# DDRSS0_CTL_CFG register map
Vendor: Texas Instruments
Peripheral module from a debugger description file (folder am65x).
Registers are 32-bit, read-write, reset 0x0 unless marked. A register's access mark holds for its fields unless they carry their own. Offsets are as the file gives them; lines under a group give offsets from that group; [hi:lo] are bit positions; {n}, {i} and the like mark numbered series; 'fields as' and 'values as' point back to an identical list; <NAME> marks a mode.

## DDRSS0_CTL_CFG (part 1 of 5)
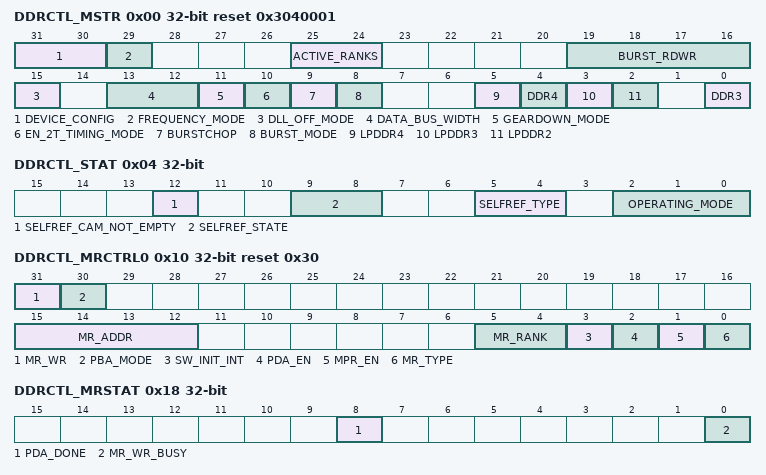
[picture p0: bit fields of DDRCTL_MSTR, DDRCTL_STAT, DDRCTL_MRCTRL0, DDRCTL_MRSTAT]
0x00 DDRCTL_MSTR reset 0x3040001 — Master Register0
  [31:30] DEVICE_CONFIG — Indicates the configuration of the device used in the system.- 00 - x4 device - 01 - x8 device - 10 - x16 device - 11 - x32 device Programming Mode: Static
  [29] FREQUENCY_MODE — Choose which registers are used.- 0 - Original registers - 1 - When UMCTL2_FREQUENCY_NUM=2: FREQ1 registers When UMCTL2_FREQUENCY_NUM&gt;2: Choosen by MSTR2.target_frequency register Programming Mode: Quasi-dynamic Group 2
  [25:24] ACTIVE_RANKS — Only present for multi-rank configurations.Each bit represents one rank. For two-rank configurations, only bits[25:24] are present. - 1 - populated - 0 - unpopulated LSB is the lowest rank number. For 2 ranks following combinations are legal: - 01 - One rank - 11 - Two ranks - Others - Reserved. For 4 ranks following combinations are legal: - 0001 - One rank - 0011 - Two ranks - 0111 - Three ranks - 1111 - Four ranks Programming Mode: Static
  [19:16] BURST_RDWR — SDRAM burst length used: -0001 - Burst length of 2 (only supported for mDDR) - 0010 - Burst length of 4 - 0100 - Burst length of 8 - 1000 - Burst length of 16 (only supported for mDDR, LPDDR2, and LPDDR4) All other values are reserved. This controls the burst size used to access the SDRAM. This must match the burst length mode register setting in the SDRAM. (For BC4/8 on-the-fly mode of DDR3 and DDR4, set this field to 0x0100) Burst length of 2 is not supported with AXI ports when MEMC_BURST_LENGTH is 8. Burst length of 2 is only supported when the controller is operating in 1:1 frequency mode. For DDR3, DDR4 and LPDDR3, this must be set to 0x0100 (BL8). For LPDDR4, this must be set to 0x1000 (BL16). Programming Mode: Static
  [15] DLL_OFF_MODE — Set to 1 when the uMCTL2 and DRAM has to be put in DLL-off mode for low frequency operation.Set to 0 to put uMCTL2 and DRAM in DLL-on mode for normal frequency operation. If DDR4 CRC/parity retry is enabled (DDRCTL_CRCPARCTL1.crc_parity_retry_enable = 1), dll_off_mode is not supported, and this bit must be set to '0'. Programming Mode: Quasi-dynamic Group 2
  [13:12] DATA_BUS_WIDTH — Selects proportion of DQ bus width that is used by the SDRAM -00 - Full DQ bus width to SDRAM - 01 - Half DQ bus width to SDRAM - 10 - Quarter DQ bus width to SDRAM - 11 - Reserved. Note that half bus width mode is only supported when the SDRAM bus width is a multiple of 16, and quarter bus width mode is only supported when the SDRAM bus width is a multiple of 32 and the configuration parameter MEMC_QBUS_SUPPORT is set. Bus width refers to DQ bus width (excluding any ECC width). Programming Mode: Static
  [11] GEARDOWN_MODE — 1 indicates put the DRAM in geardown mode (2N) and 0 indicates put the DRAM in normal mode (1N).This register can be changed, only when the Controller is in self-refresh mode. This signal must be set the same value as MR3 bit A3. Note: Geardown mode is not supported if the configuration parameter MEMC_CMD_RTN2IDLE is set Note: Geardown mode is not supported if the configuration parameter UMCTL2_SHARED_AC is set (in Shared-AC mode) and the register value is don't care Programming Mode: Quasi-dynamic Group 2
  [10] EN_2T_TIMING_MODE — If 1, then uMCTL2 uses 2T timing.Otherwise, uses 1T timing. In 2T timing, all command signals (except chip select) are held for 2 clocks on the SDRAM bus. Chip select is asserted on the second cycle of the command Note: 2T timing is not supported in LPDDR2/LPDDR3/LPDDR4 mode Note: 2T timing is not supported if the configuration parameter MEMC_CMD_RTN2IDLE is set Note: 2T timing is not supported in DDR4 geardown mode. Note: 2T timing is not supported in Shared-AC dual channel mode and the register value is don't care. Programming Mode: Static
  [9] BURSTCHOP — When set, enable burst-chop (BC4 or 8 on-the-fly) in DDR3/DDR4.Burst Chop for Reads is exercised only in HIF configurations (UMCTL2_INCL_ARB not set) and if in full bus width mode (DDRCTL_MSTR.data_bus_width = 00) and if MEMC_BURST_LENGTH=8 or 16. Burst Chop for Writes is exercised only if Partial Writes enabled (UMCTL2_PARTIAL_WR=1) and if CRC is disabled (DDRCTL_CRCPARCTL1.crc_enable = 0). If DDR4 CRC/parity retry is enabled (DDRCTL_CRCPARCTL1.crc_parity_retry_enable = 1), burst chop is not supported, and this bit must be set to '0'. BC4 (fixed) mode is not supported. Programming Mode: Static
  [8] BURST_MODE — Indicates burst mode.0 - Sequential burst mode 1 - Interleaved burst mode For LPDDR3 and LPDDR4, this must be set to 0 (sequential mode). Programming Mode: Static
  [5] LPDDR4 — Select LPDDR4 SDRAM -1 - LPDDR4 SDRAM device in use. - 0 - non-LPDDR4 device in use Present only in designs configured to support LPDDR4. Programming Mode: Static
  [4] DDR4 — Select DDR4 SDRAM -1 - DDR4 SDRAM device in use. - 0 - non-DDR4 device in use Present only in designs configured to support DDR4. Programming Mode: Static
  [3] LPDDR3 — Select LPDDR3 SDRAM -1 - LPDDR3 SDRAM device in use. - 0 - non-LPDDR3 device in use Present only in designs configured to support LPDDR3. Programming Mode: Static
  [2] LPDDR2 — Select LPDDR2 SDRAM -1 - LPDDR2 SDRAM device in use. - 0 - non-LPDDR2 device in use Present only in designs configured to support LPDDR2. Programming Mode: Static
  [0] DDR3 — Select DDR3 SDRAM -1 - DDR3 SDRAM device in use - 0 - non-DDR3 SDRAM device in use Only present in designs that support DDR3. Programming Mode: Static
0x04 DDRCTL_STAT ro — Operating Mode Status Register
  [12] SELFREF_CAM_NOT_EMPTY — Self refresh with CAMs not empty.Set to 1 when Self Refresh is entered but CAMs are not drained. Cleared after exiting Self Refresh. Programming Mode: Dynamic
  [9:8] SELFREF_STATE — Self refresh state.This indicates self refresh or self refresh power down state for LPDDR4. This register is used for frequency change and MRR/MRW access during self refresh. - 00 - SDRAM is not in Self Refresh. - 01 - Self refresh 1 - 10 - Self refresh power down - 11 - Self refresh 2 Programming Mode: Dynamic
  [5:4] SELFREF_TYPE — Flags if Self Refresh (except LPDDR4) or SR-Powerdown (LPDDR4) is entered and if it was under Automatic Self Refresh control only or not.- 00 - SDRAM is not in Self Refresh (except LPDDR4) or SR-Powerdown (LPDDR4). If retry is enabled by CRCPARCTRL1.crc_parity_retry_enable, this also indicates SRE command is still in parity error window or retry is in-progress. - 11 - SDRAM is in Self Refresh (except LPDDR4) or SR-Powerdown (LPDDR4), which was caused by Automatic Self Refresh only. If retry is enabled, this guarantees SRE command is executed correctly without parity error. - 10 - SDRAM is in Self Refresh (except LPDDR4) or SR-Powerdown (LPDDR4), which was not caused solely under Automatic Self Refresh control. It could have been caused by Hardware Low Power Interface and/or Software (DDRCTL_PWRCTL.selfref_sw). If retry is enabled, this guarantees SRE command is executed correctly without parity error. - 01 - SDRAM is in Self Refresh, which was caused by PHY Master Request. Programming Mode: Dynamic
  [2:0] OPERATING_MODE — Operating mode.This is 3-bits wide in configurations with mDDR/LPDDR2/LPDDR3/LPDDR4/DDR4 support and 2-bits in all other configurations. non-mDDR/LPDDR2/LPDDR3/LPDDR4 and non-DDR4 designs: - 00 - Init - 01 - Normal - 10 - Power-down - 11 - Self refresh mDDR/LPDDR2/LPDDR3 or DDR4 designs: - 000 - Init - 001 - Normal - 010 - Power-down - 011 - Self refresh - 1XX - Deep power-down / Maximum Power Saving Mode LPDDR4 designs: - 000 - Init - 001 - Normal - 010 - Power-down - 011 - Self refresh / Self refresh power-down Programming Mode: Dynamic
0x10 DDRCTL_MRCTRL0 access not given reset 0x30 — Mode Register Read/Write Control Register 0. Note: Do not enable more than one of the following fields simultaneously: - sw_init_int - pda_en - mpr_en
  [31] MR_WR — Setting this register bit to 1 triggers a mode register read or write operation.When the MR operation is complete, the uMCTL2 automatically clears this bit. The other register fields of this register must be written in a separate APB transaction, before setting this mr_wr bit. It is recommended NOT to set this signal if in Init, Deep power-down or MPSM operating modes. Programming Mode: Dynamic (access W1S)
  [30] PBA_MODE rw — Indicates whether PBA access is executed.When setting this bit to 1 along with setting pda_en to 1, uMCTL2 initiates PBA access instead of PDA access. - 0 - Per DRAM Addressability mode - 1 - Per Buffer Addressability mode The completion of PBA access is confirmed by DDRCTL_MRSTAT.pda_done in the same way as PDA. Programming Mode: Dynamic
  [15:12] MR_ADDR rw — Address of the mode register that is to be written to.- 0000 - MR0 - 0001 - MR1 - 0010 - MR2 - 0011 - MR3 - 0100 - MR4 - 0101 - MR5 - 0110 - MR6 - 0111 - MR7 Don't Care for LPDDR2/LPDDR3/LPDDR4 (see DDRCTL_MRCTRL1.mr_data for mode register addressing in LPDDR2/LPDDR3/LPDDR4) This signal is also used for writing to control words of the register chip on RDIMMs/LRDIMMs. In that case, it corresponds to the bank address bits sent to the RDIMM/LRDIMM In case of DDR4, the bit[3:2] corresponds to the bank group bits. Therefore, the bit[3] as well as the bit[2:0] must be set to an appropriate value which is considered both the Address Mirroring of UDIMMs/RDIMMs/LRDIMMs and the Output Inversion of RDIMMs/LRDIMMs. Programming Mode: Dynamic
  [5:4] MR_RANK rw — Controls which rank is accessed byDDRCTL_MRCTRL0.mr_wr. Normally, it is desired to access all ranks, so all bits should be set to 1. However, for multi-rank UDIMMs/RDIMMs/LRDIMMs which implement address mirroring, it may be necessary to access ranks individually. Examples (assume uMCTL2 is configured for 4 ranks): - 0x1 - select rank 0 only - 0x2 - select rank 1 only - 0x5 - select ranks 0 and 2 - 0xA - select ranks 1 and 3 - 0xF - select ranks 0, 1, 2 and 3 Programming Mode: Dynamic
  [3] SW_INIT_INT rw — Indicates whether Software intervention is allowed viaDDRCTL_MRCTRL0/DDRCTL_MRCTRL1 before automatic SDRAM initialization routine or not. For DDR4, this bit can be used to initialize the DDR4 RCD (MR7) before automatic SDRAM initialization. For LPDDR4, this bit can be used to program additional mode registers before automatic SDRAM initialization if necessary. In LPDDR4 dual channel mode, note that this must be programmed to both channels beforehand. Note that this must be cleared to 0 after completing Software operation. Otherwise, SDRAM initialization routine will not re-start. - 0 - Software intervention is not allowed - 1 - Software intervention is allowed Programming Mode: Dynamic
  [2] PDA_EN rw — Indicates whether the mode register operation is MRS in PDA mode or not -0 - MRS - 1 - MRS in Per DRAM Addressability mode Note that when pba_mode=1, PBA access is initiated instead of PDA access. Programming Mode: Dynamic
  [1] MPR_EN rw — Indicates whether the mode register operation is MRS or WR/RD for MPR (only supported for DDR4) -0 - MRS - 1 - WR/RD for MPR Programming Mode: Dynamic
  [0] MR_TYPE rw — Indicates whether the mode register operation is read or write.Only used for LPDDR2/LPDDR3/LPDDR4/DDR4. - 0 - Write - 1 - Read Programming Mode: Dynamic
0x14 DDRCTL_MRCTRL1 — Mode Register Read/Write Control Register 1
  [17:0] MR_DATA — Mode register write data for all non-LPDDR2/non-LPDDR3/non-LPDDR4 modes.For LPDDR2/LPDDR3/LPDDR4, DDRCTL_MRCTRL1[15:0] are interpreted as [15:8] MR Address [7:0] MR data for writes, don't care for reads. This is 18-bits wide in configurations with DDR4 support and 16-bits in all other configurations. Programming Mode: Dynamic
0x18 DDRCTL_MRSTAT ro — Mode Register Read/Write Status Register
  [8] PDA_DONE — The SoC core may initiate a MR write operation in PDA/PBA mode only if this signal is low.This signal goes high when three consecutive MRS commands related to the PDA/PBA mode are issued to the SDRAM. This signal goes low when DDRCTL_MRCTRL0.pda_en becomes 0. Therefore, it is recommended to write DDRCTL_MRCTRL0.pda_en to 0 after this signal goes high in order to prepare to perform PDA operation next time. - 0 - Indicates that mode register write operation related to PDA/PBA is in progress or has not started yet. - 1 - Indicates that mode register write operation related to PDA/PBA has competed. Programming Mode: Dynamic
  [0] MR_WR_BUSY — The SoC core may initiate a MR write operation only if this signal is low.This signal goes high in the clock after the uMCTL2 accepts the MRW/MRR request. It goes low when the MRW/MRR command is issued to the SDRAM. It is recommended not to perform MRW/MRR commands when 'DDRCTL_MRSTAT.mr_wr_busy' is high. - 0 - Indicates that the SoC core can initiate a mode register write operation - 1 - Indicates that mode register write operation is in progress Programming Mode: Dynamic
0x1C DDRCTL_MRCTRL2 — Mode Register Read/Write Control Register 2
  [31:0] MR_DEVICE_SEL — Indicates the device(s) to be selected during the MRS that happens in PDA mode.Each bit is associated with one device. For example, bit[0] corresponds to Device 0, bit[1] to Device 1 etc. A '1' should be programmed to indicate that the MRS command should be applied to that device. A '0' indicates that the MRS commands should be skipped for that device. Programming Mode: Dynamic
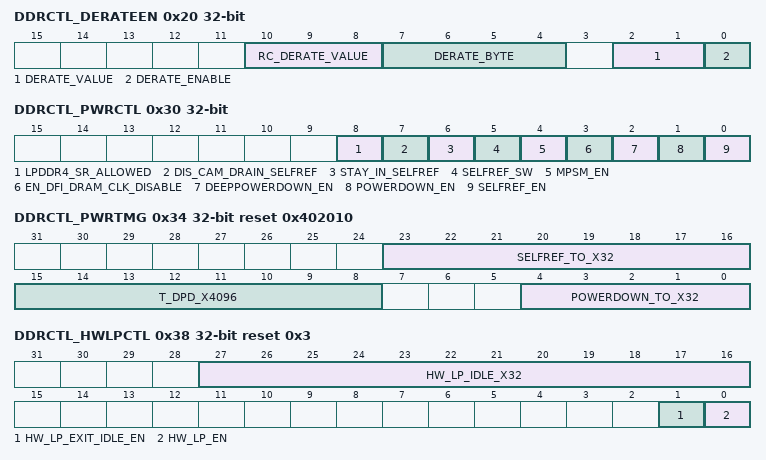
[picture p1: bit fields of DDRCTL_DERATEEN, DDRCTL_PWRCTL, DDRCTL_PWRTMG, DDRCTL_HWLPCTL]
0x20 DDRCTL_DERATEEN — Temperature Derate Enable Register
  [10:8] RC_DERATE_VALUE — Derate value of tRC for LPDDR4 - 0 - Derating uses +1. - 1 - Derating uses +2. - 2 - Derating uses +3. - 3 - Derating uses +4. Present only in designs configured to support LPDDR4. The required number of cycles for derating can be determined by dividing 3.75ns by the core_ddrc_core_clk period, and rounding up the next integer. Programming Mode: Quasi-dynamic Group 2 and Group 4
  [7:4] DERATE_BYTE — Derate byte Present only in designs configured to support LPDDR2/LPDDR3/LPDDR4 Indicates which byte of the MRR data is used for derating.The maximum valid value depends on MEMC_DRAM_TOTAL_DATA_WIDTH. Programming Mode: Static
  [2:1] DERATE_VALUE — Derate value -0 - Derating uses +1. - 1 - Derating uses +2. Present only in designs configured to support LPDDR2/LPDDR3/LPDDR4 Set to 0 for all LPDDR2 speed grades as derating value of +1.875 ns is less than a core_ddrc_core_clk period. For LPDDR3/4, if the period of core_ddrc_core_clk is less than 1.875ns, this register field should be set to 1 otherwise it should be set to 0. Programming Mode: Quasi-dynamic Group 2 and Group 4
  [0] DERATE_ENABLE — Enables derating -0 - Timing parameter derating is disabled - 1 - Timing parameter derating is enabled using MR4 read value. Present only in designs configured to support LPDDR2/LPDDR3/LPDDR4 This field must be set to '0' for non-LPDDR2/LPDDR3/LPDDR4 mode. Programming Mode: Dynamic
0x24 DDRCTL_DERATEINT reset 0x800000 — Temperature Derate Interval Register
  [31:0] MR4_READ_INTERVAL — Interval between two MR4 reads, used to derate the timing parameters.Present only in designs configured to support LPDDR2/LPDDR3/LPDDR4. This register must not be set to zero. Unit: DFI clock cycle. Programming Mode: Static
0x30 DDRCTL_PWRCTL — Low Power Control Register
  [8] LPDDR4_SR_ALLOWED — Indicates whether transition from SR-PD to SR and back to SR-PD is allowed.This register field cannot be modified while DDRCTL_PWRCTL.selfref_sw==1. - 0 - SR-PD -&gt; SR -&gt; SR-PD not allowed - 1 - SR-PD -&gt; SR -&gt; SR-PD allowed Programming Mode: Dynamic
  [7] DIS_CAM_DRAIN_SELFREF — Indicates whether skipping CAM draining is allowed when entering Self-Refresh.This register field cannot be modified while DDRCTL_PWRCTL.selfref_sw==1. - 0 - CAMs must be empty before entering SR - 1 - CAMs are not emptied before entering SR Programming Mode: Dynamic
  [6] STAY_IN_SELFREF — Self refresh state is an intermediate state to enter to Self refresh power down state or exit Self refresh power down state for LPDDR4.This register controls transition from the Self refresh state. - 1 - Prohibit transition from Self refresh state - 0 - Allow transition from Self refresh state Programming Mode: Dynamic
  [5] SELFREF_SW — A value of 1 to this register causes system to move to Self Refresh state immediately, as long as it is not in INIT or DPD/MPSM operating_mode.This is referred to as Software Entry/Exit to Self Refresh. - 1 - Software Entry to Self Refresh - 0 - Software Exit from Self Refresh Programming Mode: Dynamic
  [4] MPSM_EN — When this is 1, the uMCTL2 puts the SDRAM into maximum power saving mode when the transaction store is empty.This register must be reset to '0' to bring uMCTL2 out of maximum power saving mode. Present only in designs configured to support DDR4. For non-DDR4, this register should not be set to 1. Note that MPSM is not supported when using a DWC DDR PHY, if the PHY parameter DWC_AC_CS_USE is disabled, as the MPSM exit sequence requires the chip-select signal to toggle. FOR PERFORMANCE ONLY. Programming Mode: Dynamic
  [3] EN_DFI_DRAM_CLK_DISABLE — Enable the assertion of dfi_dram_clk_disable whenever a clock is not required by the SDRAM.If set to 0, dfi_dram_clk_disable is never asserted. Assertion of dfi_dram_clk_disable is as follows: In DDR2/DDR3, can only be asserted in Self Refresh. In DDR4, can be asserted in following: - in Self Refresh. - in Maximum Power Saving Mode In mDDR/LPDDR2/LPDDR3, can be asserted in following: - in Self Refresh - in Power Down - in Deep Power Down - during Normal operation (Clock Stop) In LPDDR4, can be asserted in following: - in Self Refresh Power Down - in Power Down - during Normal operation (Clock Stop) Programming Mode: Dynamic
  [2] DEEPPOWERDOWN_EN — When this is 1, uMCTL2 puts the SDRAM into deep power-down mode when the transaction store is empty.This register must be reset to '0' to bring uMCTL2 out of deep power-down mode. Controller performs automatic SDRAM initialization on deep power-down exit. Present only in designs configured to support mDDR or LPDDR2 or LPDDR3. For non-mDDR/non-LPDDR2/non-LPDDR3, this register should not be set to 1. FOR PERFORMANCE ONLY. Programming Mode: Dynamic
  [1] POWERDOWN_EN — If true then the uMCTL2 goes into power-down after a programmable number of cycles 'maximum idle clocks before power down' (DDRCTL_PWRTMG.powerdown_to_x32). This register bit may be re-programmed during the course of normal operation. Programming Mode: Dynamic
  [0] SELFREF_EN — If true then the uMCTL2 puts the SDRAM into Self Refresh after a programmable number of cycles 'maximum idle clocks before Self Refresh (DDRCTL_PWRTMG.selfref_to_x32)'. This register bit may be re-programmed during the course of normal operation. Programming Mode: Dynamic
0x34 DDRCTL_PWRTMG reset 0x402010 — Low Power Timing Register
  [23:16] SELFREF_TO_X32 — After this many clocks of the DDRC command channel being idle the uMCTL2 automatically puts the SDRAM into Self Refresh.The DDRC command channel is considered idle when there are no HIF commands outstanding. This must be enabled in the DDRCTL_PWRCTL.selfref_en. Unit: Multiples of 32 DFI clocks. FOR PERFORMANCE ONLY. Programming Mode: Static
  [15:8] T_DPD_X4096 — Minimum deep power-down time.For mDDR, value from the JEDEC specification is 0 as mDDR exits from deep power-down mode immediately after DDRCTL_PWRCTL.deeppowerdown_en is de-asserted. For LPDDR2/LPDDR3, value from the JEDEC specification is 500us. Unit: Multiples of 4096 DFI clocks. Present only in designs configured to support mDDR, LPDDR2 or LPDDR3. FOR PERFORMANCE ONLY. Programming Mode: Static
  [4:0] POWERDOWN_TO_X32 — After this many clocks of the DDRC command channel being idle the uMCTL2 automatically puts the SDRAM into power-down.The DDRC command channel is considered idle when there are no HIF commands outstanding. This must be enabled in the DDRCTL_PWRCTL.powerdown_en. Unit: Multiples of 32 DFI clocks FOR PERFORMANCE ONLY. Programming Mode: Static
0x38 DDRCTL_HWLPCTL reset 0x3 — Hardware Low Power Control Register
  [27:16] HW_LP_IDLE_X32 — Hardware idle period.The cactive_ddrc output is driven low if the DDRC command channel is idle for hw_lp_idle * 32 cycles if not in INIT or DPD/MPSM operating_mode. The DDRC command channel is considered idle when there are no HIF commands outstanding. The hardware idle function is disabled when hw_lp_idle_x32=0. Unit: Multiples of 32 DFI clocks. FOR PERFORMANCE ONLY. Programming Mode: Static
  [1] HW_LP_EXIT_IDLE_EN — When this bit is programmed to 1 the cactive_in_ddrc pin of the DDRC can be used to exit from the automatic clock stop, automatic power down or automatic self-refresh modes.Note, it will not cause exit of Self-Refresh that was caused by Hardware Low Power Interface and/or Software (DDRCTL_PWRCTL.selfref_sw). Programming Mode: Static
  [0] HW_LP_EN — Enable for Hardware Low Power Interface.Programming Mode: Quasi-dynamic Group 3
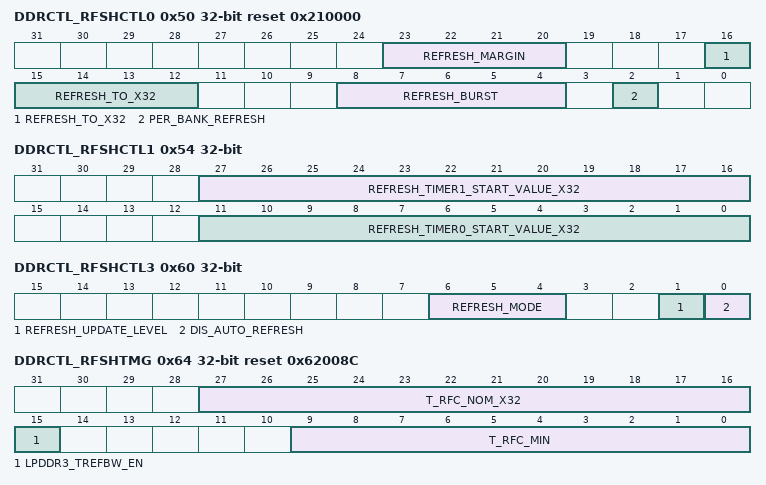
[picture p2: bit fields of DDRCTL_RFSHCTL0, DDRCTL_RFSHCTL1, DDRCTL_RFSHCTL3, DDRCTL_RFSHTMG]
0x50 DDRCTL_RFSHCTL0 reset 0x210000 — Refresh Control Register 0
  [23:20] REFRESH_MARGIN — Threshold value in number of DFI clock cycles before the critical refresh or page timer expires.A critical refresh is to be issued before this threshold is reached. It is recommended that this not be changed from the default value, currently shown as 0x2. It must always be less than internally used t_rfc_nom_x32. Note that, in LPDDR2/LPDDR3/LPDDR4, internally used t_rfc_nom_x32 may be equal to DDRCTL_RFSHTMG.t_rfc_nom_x32&gt;&gt;2 if derating is enabled (DDRCTL_DERATEEN.derate_enable=1). Otherwise, internally used t_rfc_nom_x32 will be equal to DDRCTL_RFSHTMG.t_rfc_nom_x32. Unit: Multiples of 32 DFI clocks. Programming Mode: Dynamic - Refresh Related
  [16:12] REFRESH_TO_X32 — If the refresh timer (tRFCnom, also known as tREFI) has expired at least once, but it has not expired (DDRCTL_RFSHCTL0.refresh_burst+1) times yet, then a speculative refresh may be performed. A speculative refresh is a refresh performed at a time when refresh would be useful, but before it is absolutely required. When the SDRAM bus is idle for a period of time determined by this DDRCTL_RFSHCTL0.refresh_to_x32 and the refresh timer has expired at least once since the last refresh, then a speculative refresh is performed. Speculative refreshes continues successively until there are no refreshes pending or until new reads or writes are issued to the uMCTL2. FOR PERFORMANCE ONLY. Unit: Multiples of 32 DFI clocks. Programming Mode: Dynamic - Refresh Related
  [8:4] REFRESH_BURST — The programmed value + 1 is the number of refresh timeouts that is allowed to accumulate before traffic is blocked and the refreshes are forced to execute.Closing pages to perform a refresh is a one-time penalty that must be paid for each group of refreshes. Therefore, performing refreshes in a burst reduces the per-refresh penalty of these page closings. Higher numbers for RFSHCTL.refresh_burst slightly increases utilization lower numbers decreases the worst-case latency associated with refreshes. - 0 - single refresh - 1 - burst-of-2 refresh - 7 - burst-of-8 refresh For information on burst refresh feature refer to section 3.9 of DDR2 JEDEC specification - JESD79-2F.pdf. For DDR2/3, the refresh is always per-rank and not per-bank. The rank refresh can be accumulated over 8*tREFI cycles using the burst refresh feature. In DDR4 mode, according to Fine Granularity feature, 8 refreshes can be postponed in 1X mode, 16 refreshes in 2X mode and 32 refreshes in 4X mode. If using PHY-initiated updates, care must be taken in the setting of DDRCTL_RFSHCTL0.refresh_burst, to ensure that tRFCmax is not violated due to a PHY-initiated update occurring shortly before a refresh burst was due. In this situation, the refresh burst will be delayed until the PHY-initiated update is complete. Programming Mode: Dynamic - Refresh Related
  [2] PER_BANK_REFRESH — -1 - Per bank refresh - 0 - All bank refresh. Per bank refresh allows traffic to flow to other banks. Per bank refresh is not supported by all LPDDR2 devices but should be supported by all LPDDR3/LPDDR4 devices. Present only in designs configured to support LPDDR2/LPDDR3/LPDDR4 Programming Mode: Static
0x54 DDRCTL_RFSHCTL1 — Refresh Control Register 1
  [27:16] REFRESH_TIMER1_START_VALUE_X32 — Refresh timer start for rank 1 (only present in multi-rank configurations).This is useful in staggering the refreshes to multiple ranks to help traffic to proceed. This is explained in Refresh Controls section of architecture chapter. Unit: Multiples of 32 DFI clock cycles. FOR PERFORMANCE ONLY. Programming Mode: Dynamic - Refresh Related
  [11:0] REFRESH_TIMER0_START_VALUE_X32 — Refresh timer start for rank 0 (only present in multi-rank configurations).This is useful in staggering the refreshes to multiple ranks to help traffic to proceed. This is explained in Refresh Controls section of architecture chapter. Unit: Multiples of 32 DFI clock cycles. FOR PERFORMANCE ONLY. Programming Mode: Dynamic - Refresh Related
0x60 DDRCTL_RFSHCTL3 — Refresh Control Register 3
  [6:4] REFRESH_MODE — Fine Granularity Refresh Mode -000 - Fixed 1x (Normal mode) - 001 - Fixed 2x - 010 - Fixed 4x - 101 - Enable on the fly 2x (not supported) - 110 - Enable on the fly 4x (not supported) - Everything else - reserved Note: Only Fixed 1x mode is supported if DDRCTL_RFSHCTL3.dis_auto_refresh = 1. Note: The on-the-fly modes are not supported in this version of the uMCTL2. Note: This must be set up while the Controller is in reset or while the Controller is in self-refresh mode. Changing this during normal operation is not allowed. Making this a dynamic register will be supported in future version of the uMCTL2. Note: This register field has effect only if a DDR4 SDRAM device is in use (DDRCTL_MSTR.ddr4 = 1). Programming Mode: Quasi-dynamic Group 2
  [1] REFRESH_UPDATE_LEVEL — Toggle this signal (either from 0 to 1 or from 1 to 0) to indicate that the refresh register(s) have been updated.refresh_update_level must not be toggled when the DDRC is in reset (core_ddrc_rstn = 0). The refresh register(s) are automatically updated when exiting reset. Programming Mode: Dynamic
  [0] DIS_AUTO_REFRESH — When '1', disable auto-refresh generated by the uMCTL2.When auto-refresh is disabled, the SoC core must generate refreshes using the registers DDRCTL_DBGCMD.rankn_refresh. When dis_auto_refresh transitions from 0 to 1, any pending refreshes are immediately scheduled by the uMCTL2. If DDR4 CRC/parity retry is enabled (DDRCTL_CRCPARCTL1.crc_parity_retry_enable = 1), disable auto-refresh is not supported, and this bit must be set to '0'. (DDR4 only) If FGR mode is enabled (DDRCTL_RFSHCTL3.refresh_mode &gt; 0), disable auto-refresh is not supported, and this bit must be set to '0'. This register field is changeable on the fly. Programming Mode: Dynamic - Refresh Related
0x64 DDRCTL_RFSHTMG reset 0x62008C — Refresh Timing Register
  [27:16] T_RFC_NOM_X32 — tREFI: Average time interval between refreshes per rank (Specification: 7.8us for DDR2, DDR3 and DDR4.See JEDEC specification for mDDR, LPDDR2, LPDDR3 and LPDDR4). For LPDDR2/LPDDR3/LPDDR4: - if using all-bank refreshes (DDRCTL_RFSHCTL0.per_bank_refresh = 0), this register should be set to tREFIab - if using per-bank refreshes (DDRCTL_RFSHCTL0.per_bank_refresh = 1), this register should be set to tREFIpb When the controller is operating in 1:2 frequency ratio mode, program this to (tREFI/2), no rounding up. In DDR4 mode, tREFI value is different depending on the refresh mode. The user should program the appropriate value from the spec based on the value programmed in the refresh mode register. Note that DDRCTL_RFSHTMG.t_rfc_nom_x32 * 32 must be greater than DDRCTL_RFSHTMG.t_rfc_min, and DDRCTL_RFSHTMG.t_rfc_nom_x32 must be greater than 0x1. - Non-DDR4 or DDR4 Fixed 1x mode: DDRCTL_RFSHTMG.t_rfc_nom_x32 must be less than or equal to 0xFFE. - DDR4 Fixed 2x mode: DDRCTL_RFSHTMG.t_rfc_nom_x32 must be less than or equal to 0x7FF. - DDR4 Fixed 4x mode: DDRCTL_RFSHTMG.t_rfc_nom_x32 must be less than or equal to 0x3FF. Unit: Multiples of 32 clocks. Programming Mode: Dynamic - Refresh Related
  [15] LPDDR3_TREFBW_EN — Used only when LPDDR3 memory type is connected.Should only be changed when uMCTL2 is in reset. Specifies whether to use the tREFBW parameter (required by some LPDDR3 devices which comply with earlier versions of the LPDDR3 JEDEC specification) or not: - 0 - tREFBW parameter not used - 1 - tREFBW parameter used Programming Mode: Static
  [9:0] T_RFC_MIN — tRFC (min): Minimum time from refresh to refresh or activate.When the controller is operating in 1:1 mode, t_rfc_min should be set to RoundUp(tRFCmin/tCK). When the controller is operating in 1:2 mode, t_rfc_min should be set to RoundUp(RoundUp(tRFCmin/tCK)/2). In LPDDR2/LPDDR3/LPDDR4 mode: - if using all-bank refreshes, the tRFCmin value in the above equations is equal to tRFCab - if using per-bank refreshes, the tRFCmin value in the above equations is equal to tRFCpb In DDR4 mode, the tRFCmin value in the above equations is different depending on the refresh mode (fixed 1X,2X,4X) and the device density. The user should program the appropriate value from the spec based on the 'refresh_mode' and the device density that is used. Unit: Clocks. Programming Mode: Dynamic - Refresh Related
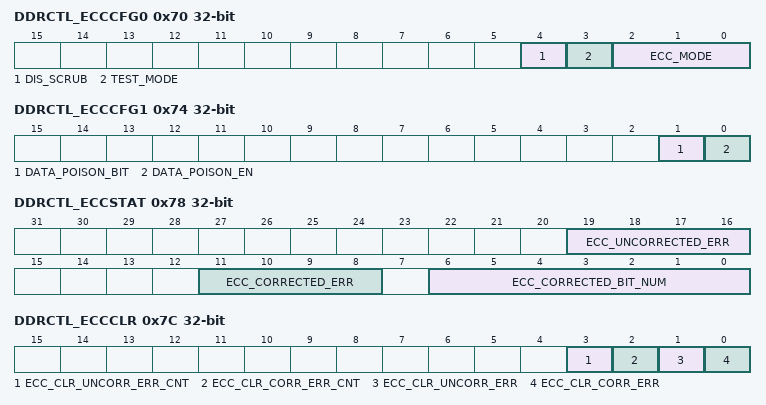
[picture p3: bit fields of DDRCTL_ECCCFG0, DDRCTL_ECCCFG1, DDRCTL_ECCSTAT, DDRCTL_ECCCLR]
0x70 DDRCTL_ECCCFG0 — ECC Configuration Register 0
  [4] DIS_SCRUB — Disable ECC scrubs.Valid only when DDRCTL_ECCCFG0.ecc_mode = 3'b100 or 3'b101 and MEMC_USE_RMW is defined. Note: Scrub is not supported in inline ECC mode and the register value is don't care. Programming Mode: Static
  [3] TEST_MODE — If this bit is set to 1, no ECC is performed, and the ECC byte is accessed directly from co_wu_rxdata_ecc and ra_co_resp_ecc_data.This test mode is only supported with the HIF interface - it is disabled if UMCTL2_INCL_ARB is enabled. This test mode is only supported in full bus width mode. In other words, if DDRCTL_MSTR.data_bus_width is non-zero, this test_mode field must be set to 0. If test_mode is set to 1, the ecc_mode field is ignored. If MEMC_ECC_SUPPORT is 2 (Advanced ECC mode), this test_mode field must be set to 0. Note: test_mode is not supported in inline ECC mode and the register value is don't care. Programming Mode: Static
  [2:0] ECC_MODE — ECC mode indicator -000 - ECC disabled - 100 - ECC enabled - SEC/DED over 1 beat - 101 - ECC enabled - Advanced ECC - all other settings are reserved for future use Programming Mode: Static
0x74 DDRCTL_ECCCFG1 — ECC Configuration Register 1
  [1] DATA_POISON_BIT — Selects whether to poison 1 or 2 bits - if0 -&gt; 2-bit (uncorrectable) data poisoning, if 1 -&gt; 1-bit (correctable) data poisoning, if DDRCTL_ECCCFG1.data_poison_en=1. Valid only when MEMC_ECC_SUPPORT==1 (SECDED ECC mode) Programming Mode: Quasi-dynamic Group 3
  [0] DATA_POISON_EN — Enable ECC data poisoning - introduces ECC errors on writes to address specified by the
0x78 DDRCTL_ECCSTAT ro — SECDED ECC Status Register (Valid only in MEMC_ECC_SUPPORT==1 (SECDED ECC mode))
  [19:16] ECC_UNCORRECTED_ERR — Double-bit error indicators.In sideband ECC mode, 1 bit per ECC lane. When the controller is operating in 1:1 frequency ratio mode, there are only two lanes, so only the lower two bits are used. In inline ECC mode, the register always is 1 bit to indicate uncorrectable error on any lane. Programming Mode: Dynamic
  [11:8] ECC_CORRECTED_ERR — Single-bit error indicators.In sideband ECC mode, 1 bit per ECC lane. When the controller is operating in 1:1 frequency ratio mode, there are only two lanes, so only the lower two bits are used. In inline ECC mode, the register always is 1 bit to indicate correctable error on any lane. Programming Mode: Dynamic
  [6:0] ECC_CORRECTED_BIT_NUM — Bit number corrected by single-bit ECC error.If more than one data lane has an error, the lower data lane is selected. This register is 7 bits wide in order to handle 72 bits of the data present in a single lane. Programming Mode: Static
0x7C DDRCTL_ECCCLR access not given — ECC Clear Register
  [3] ECC_CLR_UNCORR_ERR_CNT — Setting this register bit to 1 clears the currently stored uncorrected ECC error count.The DDRCTL_ECCERRCNT.ecc_uncorr_err_cnt register is cleared by this operation. When the clear operation is complete, the uMCTL2 automatically clears this bit. Programming Mode: Dynamic (access RW1C)
  [2] ECC_CLR_CORR_ERR_CNT — Setting this register bit to 1 clears the currently stored corrected ECC error count.The DDRCTL_ECCERRCNT.ecc_corr_err_cnt register is cleared by this operation. When the clear operation is complete, the uMCTL2 automatically clears this bit. Programming Mode: Dynamic (access RW1C)
  [1] ECC_CLR_UNCORR_ERR — Setting this register bit to 1 clears the currently stored uncorrected ECC error.The DDRCTL_ECCSTAT.ecc_uncorrected_err, ADVECCSTAT.advecc_uncorrected_err, DDRCTL_ECCUADDR0, DDRCTL_ECCUADDR1, DDRCTL_ECCUSYN0, ECCUSYN1 and DDRCTL_ECCUSYN2 registers are cleared by this operation. When the clear operation is complete, the uMCTL2 automatically clears this bit. Programming Mode: Dynamic (access RW1C)
  [0] ECC_CLR_CORR_ERR — Setting this register bit to 1 clears the currently stored corrected ECC error.The DDRCTL_ECCSTAT.ecc_corrected_err, DDRCTL_ECCSTAT.ecc_corrected_bit_num, ADVECCSTAT.advecc_corrected_err, ADVECCSTAT.advecc_num_err_symbol, ADVECCSTAT.advecc_err_symbol_pos, ADVECCSTAT.advecc_err_symbol_bits, DDRCTL_ECCCADDR0, DDRCTL_ECCCADDR1, DDRCTL_ECCCSYN0, ECCCSYN1, DDRCTL_ECCCSYN2, DDRCTL_ECCBITMASK0, ECCBITMASK1 and DDRCTL_ECCBITMASK2 registers are cleared by this operation. When the clear operation is complete, the uMCTL2 automatically clears this bit. Programming Mode: Dynamic (access RW1C)
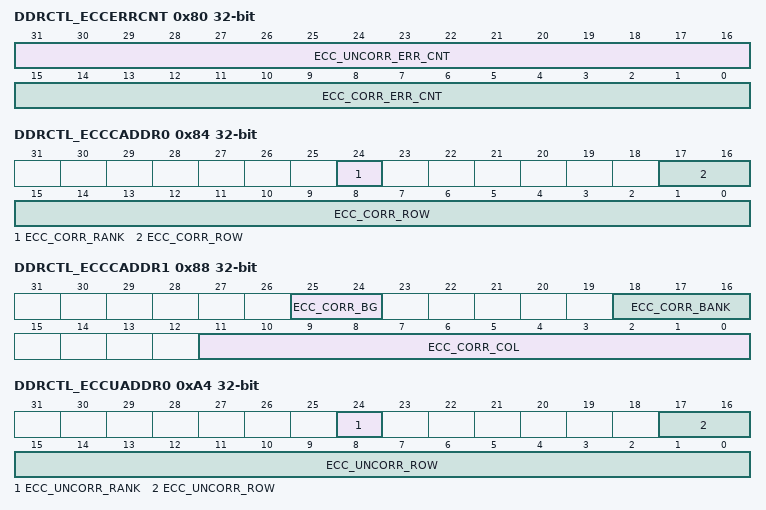
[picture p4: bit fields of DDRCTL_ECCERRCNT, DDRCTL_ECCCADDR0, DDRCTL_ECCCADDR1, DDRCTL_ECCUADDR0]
0x80 DDRCTL_ECCERRCNT ro — ECC Error Counter Register
  [31:16] ECC_UNCORR_ERR_CNT — Number of uncorrectable ECC errors detected.Note that the saturation behavior of this register is different, depending on whether SECDED ECC or advanced ECC is enabled. For advanced ECC, it saturates at 0xFFFF, while for SECDED ECC, it saturates at 0xFFFC or above. Programming Mode: Dynamic
  [15:0] ECC_CORR_ERR_CNT — Number of correctable ECC errors detected.Note that the saturation behavior of this register is different, depending on whether SECDED ECC or advanced ECC is enabled. For advanced ECC, it saturates at 0xFFFF, while for SECDED ECC, it saturates at 0xFFFC or above. Programming Mode: Dynamic
0x84 DDRCTL_ECCCADDR0 ro — ECC Corrected Error Address Register 0
  [24] ECC_CORR_RANK — Rank number of a read resulting in a corrected ECC error Programming Mode: Dynamic
  [17:0] ECC_CORR_ROW — Page/row number of a read resulting in a corrected ECC error.This is 18-bits wide in configurations with DDR4 support and 16-bits in all other configurations. Programming Mode: Dynamic
0x88 DDRCTL_ECCCADDR1 ro — ECC Corrected Error Address Register 1
  [25:24] ECC_CORR_BG — Bank Group number of a read resulting in a corrected ECC error Programming Mode: Dynamic
  [18:16] ECC_CORR_BANK — Bank number of a read resulting in a corrected ECC error Programming Mode: Dynamic
  [11:0] ECC_CORR_COL — Block number of a read resulting in a corrected ECC error (lowest bit not assigned here) Programming Mode: Dynamic
0x8C DDRCTL_ECCCSYN0 ro — ECC Corrected Syndrome Register 0
  [31:0] ECC_CORR_SYNDROMES_31_0 — Data pattern that resulted in a corrected error.For 16-bit ECC, only bits [15:0] are used Programming Mode: Dynamic
0x94 DDRCTL_ECCCSYN2 ro — ECC Corrected Syndrome Register 2
  [7:0] ECC_CORR_SYNDROMES_71_64 — Data pattern that resulted in a corrected error one for each ECC lane, all concatenated together This register refers to the ECC byte, which is bits[71:64] for 64-bit ECC, [39:32] for 32-bit ECC, or [23:16] for 16-bit ECC Programming Mode: Dynamic
0x98 DDRCTL_ECCBITMASK0 ro — ECC Corrected Data Bit Mask Register 0
  [31:0] ECC_CORR_BIT_MASK_31_0 — Mask for the corrected data portion - 1 on any bit indicates that the bit has been corrected by the ECC logic - 0 on any bit indicates that the bit has not been corrected by the ECC logic This register accumulates data over multiple ECC errors, to give an overall indication of which bits are being fixed.It is cleared by writing a 1 to DDRCTL_ECCCLR.ecc_clr_corr_err. For 16-bit ECC, only bits [15:0] are used Programming Mode: Dynamic
0xA0 DDRCTL_ECCBITMASK2 ro — ECC Corrected Data Bit Mask Register 2
  [7:0] ECC_CORR_BIT_MASK_71_64 — Mask for the corrected data portion - 1 on any bit indicates that the bit has been corrected by the ECC logic - 0 on any bit indicates that the bit has not been corrected by the ECC logic This register accumulates data over multiple ECC errors, to give an overall indication of which bits are being fixed.It is cleared by writing a 1 to DDRCTL_ECCCLR.ecc_clr_corr_err. This register refers to the ECC byte, which is bits [71:64] for 64-bit ECC, [39:32] for 32-bit ECC, or [23:16] for 16-bit ECC Programming Mode: Dynamic
0xA4 DDRCTL_ECCUADDR0 ro — ECC Uncorrected Error Address Register 0
  [24] ECC_UNCORR_RANK — Rank number of a read resulting in an uncorrected ECC error Programming Mode: Dynamic
  [17:0] ECC_UNCORR_ROW — Page/row number of a read resulting in an uncorrected ECC error.This is 18-bits wide in configurations with DDR4 support and 16-bits in all other configurations. Programming Mode: Dynamic
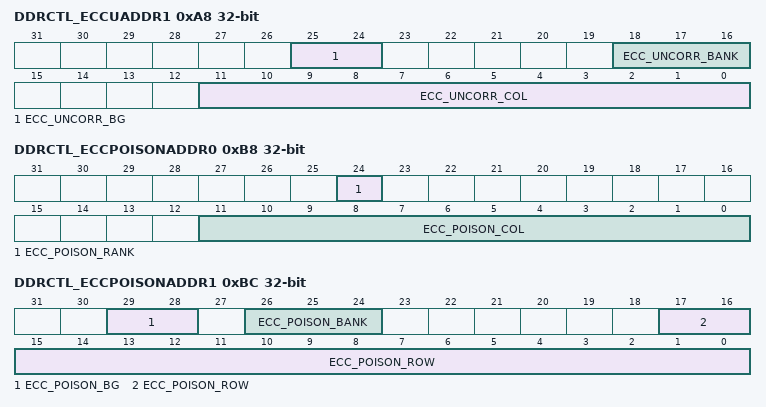
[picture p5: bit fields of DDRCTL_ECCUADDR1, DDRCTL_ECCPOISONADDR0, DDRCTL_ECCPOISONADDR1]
0xA8 DDRCTL_ECCUADDR1 ro — ECC Uncorrected Error Address Register 1
  [25:24] ECC_UNCORR_BG — Bank Group number of a read resulting in an uncorrected ECC error Programming Mode: Dynamic
  [18:16] ECC_UNCORR_BANK — Bank number of a read resulting in an uncorrected ECC error Programming Mode: Dynamic
  [11:0] ECC_UNCORR_COL — Block number of a read resulting in an uncorrected ECC error (lowest bit not assigned here) Programming Mode: Dynamic
0xAC DDRCTL_ECCUSYN0 ro — ECC Uncorrected Syndrome Register 0
  [31:0] ECC_UNCORR_SYNDROMES_31_0 — Data pattern that resulted in an uncorrected error, one for each ECC lane, all concatenated together.For 16-bit ECC, only bits [15:0] are used Programming Mode: Dynamic
0xB4 DDRCTL_ECCUSYN2 ro — ECC Uncorrected Syndrome Register 2
  [7:0] ECC_UNCORR_SYNDROMES_71_64 — Data pattern that resulted in an uncorrected error one for each ECC lane, all concatenated together.This register refers to the ECC byte, which is bits [71:64] for 64-bit ECC, [39:32] for 32-bit ECC, or [23:16] for 16-bit ECC Programming Mode: Dynamic
0xB8 DDRCTL_ECCPOISONADDR0 — ECC Data Poisoning Address Register 0. If a HIF write data beat matches the address specified in this register, an ECC error will be introduced on that transaction (write/RMW), if .data_poison_en=1
  [24] ECC_POISON_RANK — Rank address for ECC poisoning Programming Mode: Static
  [11:0] ECC_POISON_COL — Column address for ECC poisoning.Note that this column address must be burst aligned: - In full bus width mode, ecc_poison_col[2:0] must be set to 0 - In half bus width mode, ecc_poison_col[3:0] must be set to 0 - In quarter bus width mode, ecc_poison_col[4:0] must be set to 0 Programming Mode: Static
0xBC DDRCTL_ECCPOISONADDR1 — ECC Data Poisoning Address Register 1. If a HIF write data beat matches the address specified in this register, an ECC error will be introduced on that transaction (write/RMW), if .data_poison_en=1
  [29:28] ECC_POISON_BG — Bank Group address for ECC poisoning Programming Mode: Static
  [26:24] ECC_POISON_BANK — Bank address for ECC poisoning Programming Mode: Static
  [17:0] ECC_POISON_ROW — Row address for ECC poisoning.This is 18-bits wide in configurations with DDR4 support and 16-bits in all other configurations. Programming Mode: Static
